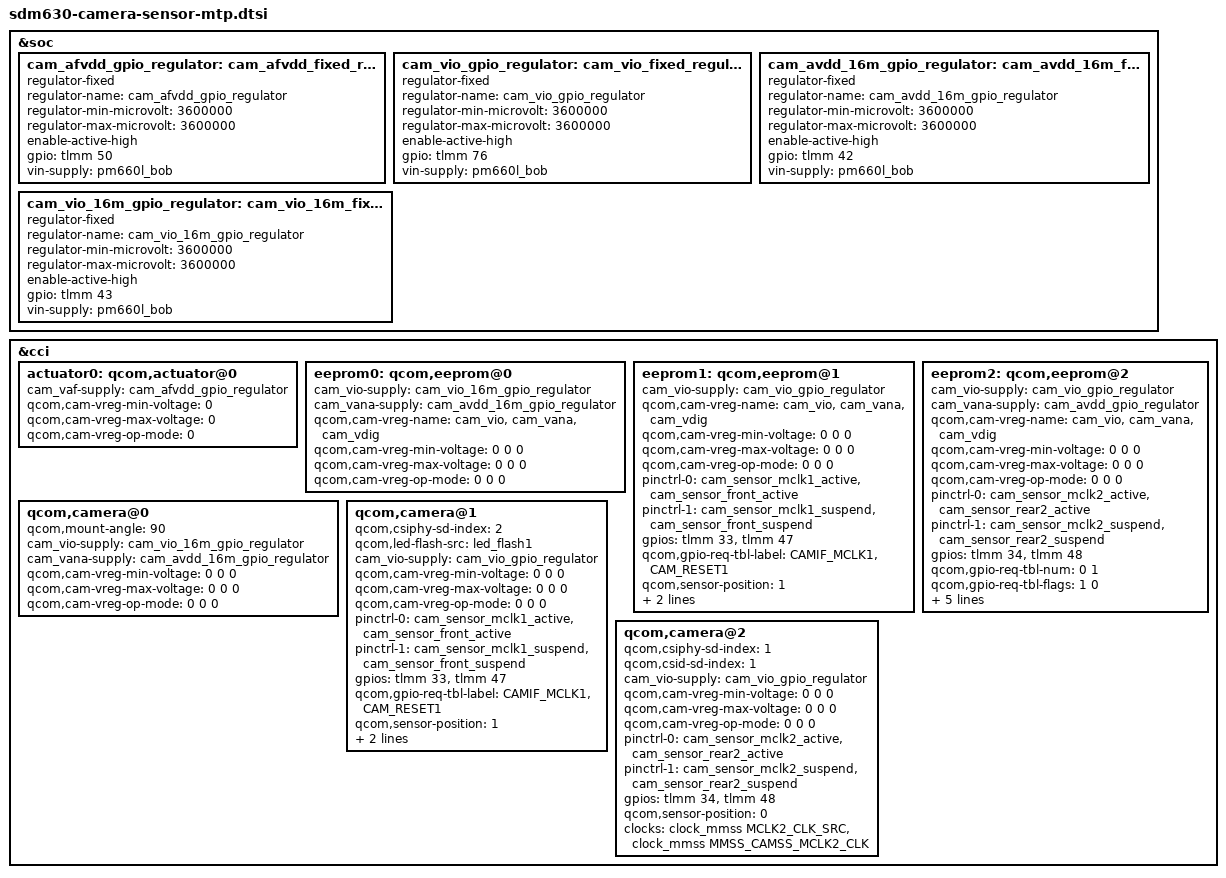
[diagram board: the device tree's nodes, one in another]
/*
 * Copyright (c) 2017, The Linux Foundation. All rights reserved.
 *
 * This program is free software; you can redistribute it and/or modify
 * it under the terms of the GNU General Public License version 2 and
 * only version 2 as published by the Free Software Foundation.
 *
 * This program is distributed in the hope that it will be useful,
 * but WITHOUT ANY WARRANTY; without even the implied warranty of
 * MERCHANTABILITY or FITNESS FOR A PARTICULAR PURPOSE.  See the
 * GNU General Public License for more details.
 */

&soc {
	cam_afvdd_gpio_regulator: cam_afvdd_fixed_regulator {
		compatible = "regulator-fixed";
		regulator-name = "cam_afvdd_gpio_regulator";
		regulator-min-microvolt = <3600000>;
		regulator-max-microvolt = <3600000>;
		enable-active-high;
		gpio = <&tlmm 50 0>;
		vin-supply = <&pm660l_bob>;
	};

	cam_vio_gpio_regulator: cam_vio_fixed_regulator {
		compatible = "regulator-fixed";
		regulator-name = "cam_vio_gpio_regulator";
		regulator-min-microvolt = <3600000>;
		regulator-max-microvolt = <3600000>;
		enable-active-high;
		gpio = <&tlmm 76 0>;
		vin-supply = <&pm660l_bob>;
	};

	cam_avdd_16m_gpio_regulator: cam_avdd_16m_fixed_regulator {
		compatible = "regulator-fixed";
		regulator-name = "cam_avdd_16m_gpio_regulator";
		regulator-min-microvolt = <3600000>;
		regulator-max-microvolt = <3600000>;
		enable-active-high;
		gpio = <&tlmm 42 0>;
		vin-supply = <&pm660l_bob>;
	};

	cam_vio_16m_gpio_regulator: cam_vio_16m_fixed_regulator {
		compatible = "regulator-fixed";
		regulator-name = "cam_vio_16m_gpio_regulator";
		regulator-min-microvolt = <3600000>;
		regulator-max-microvolt = <3600000>;
		enable-active-high;
		gpio = <&tlmm 43 0>;
		vin-supply = <&pm660l_bob>;
	};

};

&cci {
	actuator0: qcom,actuator@0 {
		cam_vaf-supply = <&cam_afvdd_gpio_regulator>;
		qcom,cam-vreg-min-voltage = <0>;
		qcom,cam-vreg-max-voltage = <0>;
		qcom,cam-vreg-op-mode = <0>;
	};
	/delete-node/ qcom,actuator@1;
	/delete-node/ qcom,actuator@2;
	/delete-node/ qcom,ois@0;
	/delete-node/ qcom,tof@29;

	eeprom0: qcom,eeprom@0 {
		cam_vio-supply = <&cam_vio_16m_gpio_regulator>;
		cam_vana-supply = <&cam_avdd_16m_gpio_regulator>;
		/delete-property/ cam_vaf-supply;
		qcom,cam-vreg-name = "cam_vio", "cam_vana", "cam_vdig";
		qcom,cam-vreg-min-voltage = <0 0 0>;
		qcom,cam-vreg-max-voltage = <0 0 0>;
		qcom,cam-vreg-op-mode = <0 0 0>;
	};

	eeprom1: qcom,eeprom@1 {
		cam_vio-supply = <&cam_vio_gpio_regulator>;
		/delete-property/ cam_vaf-supply;
		qcom,cam-vreg-name = "cam_vio", "cam_vana", "cam_vdig";
		qcom,cam-vreg-min-voltage = <0 0 0>;
		qcom,cam-vreg-max-voltage = <0 0 0>;
		qcom,cam-vreg-op-mode = <0 0 0>;
		pinctrl-0 = <&cam_sensor_mclk1_active
			&cam_sensor_front_active>;
		pinctrl-1 = <&cam_sensor_mclk1_suspend
			&cam_sensor_front_suspend>;
		gpios = <&tlmm 33 0>,
			<&tlmm 47 0>;
		qcom,gpio-req-tbl-label = "CAMIF_MCLK1",
			"CAM_RESET1";
		qcom,sensor-position = <1>;
		clocks = <&clock_mmss MCLK1_CLK_SRC>,
			<&clock_mmss MMSS_CAMSS_MCLK1_CLK>;
	};

	eeprom2: qcom,eeprom@2 {
		cam_vio-supply = <&cam_vio_gpio_regulator>;
		cam_vana-supply = <&cam_avdd_gpio_regulator>;
		qcom,cam-vreg-name = "cam_vio", "cam_vana", "cam_vdig";
		qcom,cam-vreg-min-voltage = <0 0 0>;
		qcom,cam-vreg-max-voltage = <0 0 0>;
		qcom,cam-vreg-op-mode = <0 0 0>;
		pinctrl-0 = <&cam_sensor_mclk2_active
				 &cam_sensor_rear2_active>;
		pinctrl-1 = <&cam_sensor_mclk2_suspend
				 &cam_sensor_rear2_suspend>;
		gpios = <&tlmm 34 0>,
			<&tlmm 48 0>;
		/delete-property/ qcom,gpio-vana;
		qcom,gpio-req-tbl-num = <0 1>;
		qcom,gpio-req-tbl-flags = <1 0>;
		qcom,gpio-req-tbl-label = "CAMIF_MCLK2",
					  "CAM_RESET2";
		qcom,sensor-position = <0>;
		clocks = <&clock_mmss MCLK2_CLK_SRC>,
			<&clock_mmss MMSS_CAMSS_MCLK2_CLK>;
	};

	qcom,camera@0 {
		qcom,mount-angle = <90>;
		/delete-property/ qcom,ois-src;
		cam_vio-supply = <&cam_vio_16m_gpio_regulator>;
		cam_vana-supply = <&cam_avdd_16m_gpio_regulator>;
		qcom,cam-vreg-min-voltage = <0 0 0>;
		qcom,cam-vreg-max-voltage = <0 0 0>;
		qcom,cam-vreg-op-mode = <0 0 0>;
	};

	qcom,camera@1 {
		qcom,csiphy-sd-index = <2>;
		/delete-property/ qcom,actuator-src;
		qcom,led-flash-src = <&led_flash1>;
		cam_vio-supply = <&cam_vio_gpio_regulator>; 
		qcom,cam-vreg-min-voltage = <0 0 0>;
		qcom,cam-vreg-max-voltage = <0 0 0>;
		qcom,cam-vreg-op-mode = <0 0 0>;
		pinctrl-0 = <&cam_sensor_mclk1_active
				 &cam_sensor_front_active>;
		pinctrl-1 = <&cam_sensor_mclk1_suspend
				 &cam_sensor_front_suspend>;
		gpios = <&tlmm 33 0>,
			<&tlmm 47 0>;
		qcom,gpio-req-tbl-label = "CAMIF_MCLK1",
					"CAM_RESET1";
		qcom,sensor-position = <1>;
		clocks = <&clock_mmss MCLK1_CLK_SRC>,
			<&clock_mmss MMSS_CAMSS_MCLK1_CLK>;
	};

	qcom,camera@2 {
		qcom,csiphy-sd-index = <1>;
		qcom,csid-sd-index = <1>;
		/delete-property/ qcom,actuator-src;
		cam_vio-supply = <&cam_vio_gpio_regulator>;
		qcom,cam-vreg-min-voltage = <0 0 0>;
		qcom,cam-vreg-max-voltage = <0 0 0>;
		qcom,cam-vreg-op-mode = <0 0 0>;
		pinctrl-0 = <&cam_sensor_mclk2_active
				 &cam_sensor_rear2_active>;
		pinctrl-1 = <&cam_sensor_mclk2_suspend
				 &cam_sensor_rear2_suspend>;
		gpios = <&tlmm 34 0>,
			<&tlmm 48 0>;
		qcom,sensor-position = <0>;
		clocks = <&clock_mmss MCLK2_CLK_SRC>,
			<&clock_mmss MMSS_CAMSS_MCLK2_CLK>;
	};

	/delete-node/ qcom,camera@3;
};
